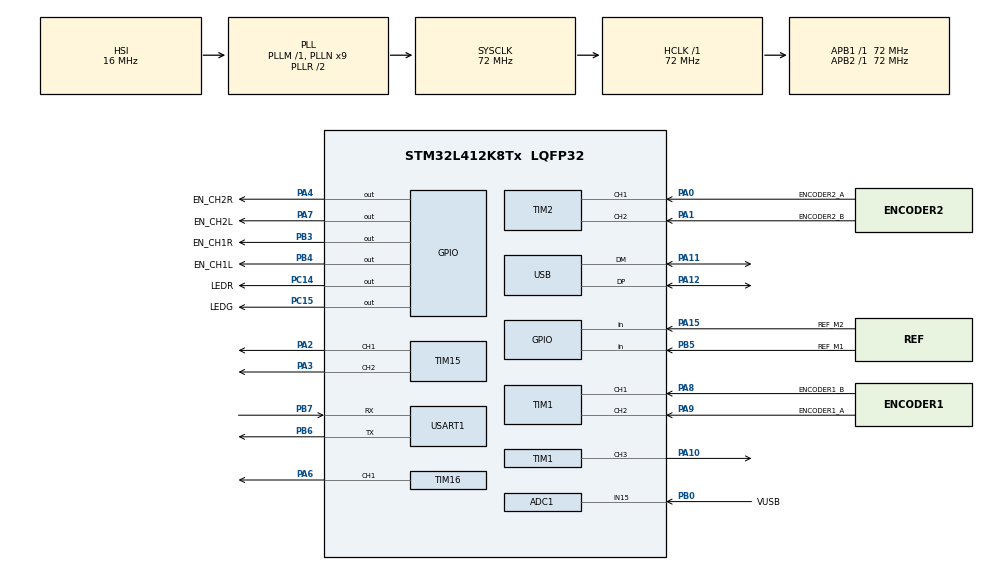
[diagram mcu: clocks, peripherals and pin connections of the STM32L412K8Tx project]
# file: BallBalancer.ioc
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ADC1.Channel-0\#ChannelRegularConversion=ADC_CHANNEL_15
ADC1.NbrOfConversionFlag=1
ADC1.OffsetNumber-0\#ChannelRegularConversion=ADC_OFFSET_NONE
ADC1.Rank-0\#ChannelRegularConversion=1
ADC1.SamplingTime-0\#ChannelRegularConversion=ADC_SAMPLETIME_2CYCLES_5
ADC1.master=1
Mcu.Family=STM32L4
Mcu.Name=STM32L412K8Tx
Mcu.Package=LQFP32
NVIC.PriorityGroup=NVIC_PRIORITYGROUP_4
NVIC.TIM6_IRQn=true\:0\:0\:false\:false\:true\:true\:true\:true
PA0-CK_IN.GPIO_Label=ENCODER2_A
PA0-CK_IN.Signal=S_TIM2_CH1
PA1.GPIO_Label=ENCODER2_B
PA1.Signal=S_TIM2_CH2
PA10.Signal=S_TIM1_CH3
PA11.Mode=Device
PA11.Signal=USB_DM
PA12.Mode=Device
PA12.Signal=USB_DP
PA13\ (JTMS/SWDIO).Mode=Serial_Wire
PA13\ (JTMS/SWDIO).Signal=SYS_JTMS-SWDIO
PA14\ (JTCK/SWCLK).Mode=Serial_Wire
PA14\ (JTCK/SWCLK).Signal=SYS_JTCK-SWCLK
PA15\ (JTDI).GPIO_Label=REF_M2
PA15\ (JTDI).Signal=GPIO_Input
PA2.Signal=S_TIM15_CH1
PA3.Signal=S_TIM15_CH2
PA4.GPIO_Label=EN_CH2R
PA4.Signal=GPIO_Output
PA6.Signal=S_TIM16_CH1
PA7.GPIO_Label=EN_CH2L
PA7.Signal=GPIO_Output
PA8.GPIO_Label=ENCODER1_B
PA8.Signal=S_TIM1_CH1
PA9.GPIO_Label=ENCODER1_A
PA9.Signal=S_TIM1_CH2
PB0.GPIO_Label=VUSB
PB0.Signal=ADCx_IN15
PB3\ (JTDO/TRACESWO).GPIO_Label=EN_CH1R
PB3\ (JTDO/TRACESWO).Signal=GPIO_Output
PB4\ (NJTRST).GPIO_Label=EN_CH1L
PB4\ (NJTRST).Signal=GPIO_Output
PB5.GPIO_Label=REF_M1
PB5.Signal=GPIO_Input
PB6.Mode=Asynchronous
PB6.Signal=USART1_TX
PB7.Mode=Asynchronous
PB7.Signal=USART1_RX
PC14-OSC32_IN\ (PC14).GPIO_Label=LEDR
PC14-OSC32_IN\ (PC14).Signal=GPIO_Output
PC15-OSC32_OUT\ (PC15).GPIO_Label=LEDG
PC15-OSC32_OUT\ (PC15).Signal=GPIO_Output
ProjectManager.HeapSize=0x200
ProjectManager.StackSize=0x400
ProjectManager.TargetToolchain=STM32CubeIDE
RCC.ADCFreq_Value=72000000
RCC.AHBFreq_Value=72000000
RCC.APB1Freq_Value=72000000
RCC.APB1TimFreq_Value=72000000
RCC.APB2Freq_Value=72000000
RCC.APB2TimFreq_Value=72000000
RCC.CK48CLockSelection=RCC_USBCLKSOURCE_HSI48
RCC.CortexFreq_Value=72000000
RCC.HCLKFreq_Value=72000000
RCC.HSE_VALUE=8000000
RCC.HSI48_VALUE=48000000
RCC.HSI_VALUE=16000000
RCC.LSE_VALUE=32768
RCC.MSI_VALUE=4000000
RCC.PLLN=9
RCC.PLLSourceVirtual=RCC_PLLSOURCE_HSI
RCC.SYSCLKFreq_VALUE=72000000
RCC.SYSCLKSource=RCC_SYSCLKSOURCE_PLLCLK
RCC.USBFreq_Value=48000000
RCC.VCOOutputFreq_Value=144000000
SH.ADCx_IN15.0=ADC1_IN15,IN15-Single-Ended
SH.S_TIM15_CH1.0=TIM15_CH1,PWM Generation1 CH1
SH.S_TIM15_CH2.0=TIM15_CH2,PWM Generation2 CH2
SH.S_TIM16_CH1.0=TIM16_CH1,PWM Generation1 CH1
SH.S_TIM1_CH1.0=TIM1_CH1,Encoder_Interface
SH.S_TIM1_CH2.0=TIM1_CH2,Encoder_Interface
SH.S_TIM1_CH3.0=TIM1_CH3,PWM Generation3 CH3
SH.S_TIM2_CH1.0=TIM2_CH1,Encoder_Interface
SH.S_TIM2_CH2.0=TIM2_CH2,Encoder_Interface
TIM1.Channel-PWM\ Generation3\ CH3=TIM_CHANNEL_3
TIM15.Channel-PWM\ Generation1\ CH1=TIM_CHANNEL_1
TIM15.Channel-PWM\ Generation2\ CH2=TIM_CHANNEL_2
TIM16.Channel=TIM_CHANNEL_1
TIM6.Period=35999
TIM6.Prescaler=2
USART1.VirtualMode-Asynchronous=VM_ASYNC
VP_TIM16_VS_ClockSourceINT.Mode=Enable_Timer
VP_TIM6_VS_ClockSourceINT.Mode=Enable_Timer
board=custom

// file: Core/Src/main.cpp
/* USER CODE BEGIN Header */
/**
  ******************************************************************************
  * @file           : main.c
  * @brief          : Main program body
  ******************************************************************************
  * @attention
  *
  * Copyright (c) 2023 STMicroelectronics.
  * All rights reserved.
  *
  * This software is licensed under terms that can be found in the LICENSE file
  * in the root directory of this software component.
  * If no LICENSE file comes with this software, it is provided AS-IS.
  *
  ******************************************************************************
  */
/* USER CODE END Header */
#include "main.h"
#include "adc.h"
#include "tim.h"
#include "usart.h"
#include "usb.h"
#include "gpio.h"

/* USER CODE BEGIN Includes */
#include "AppMain/ApplicationMain.h"
/* USER CODE END Includes */

/* USER CODE BEGIN PV */
  ApplicationMain applicationMain = ApplicationMain();
/* USER CODE END PV */

void SystemClock_Config(void);

int main(void)
{

  /* MCU Configuration--------------------------------------------------------*/

  /* Reset of all peripherals, Initializes the Flash interface and the Systick. */
  HAL_Init();

  /* Configure the system clock */
  SystemClock_Config();

  /* Initialize all configured peripherals */
  MX_GPIO_Init();
  MX_TIM1_Init();
  MX_TIM2_Init();
  MX_TIM15_Init();
  MX_TIM16_Init();
  MX_USART1_UART_Init();
  MX_USB_PCD_Init();
  MX_ADC1_Init();
  MX_TIM6_Init();
  /* USER CODE BEGIN 2 */
  applicationMain.StartUp();
  /* USER CODE END 2 */

  /* Infinite loop */
  while (1)
  {

  }
}

void SystemClock_Config(void)
{
  RCC_OscInitTypeDef RCC_OscInitStruct = {0};
  RCC_ClkInitTypeDef RCC_ClkInitStruct = {0};

  /** Configure the main internal regulator output voltage
  */
  if (HAL_PWREx_ControlVoltageScaling(PWR_REGULATOR_VOLTAGE_SCALE1) != HAL_OK)
  {
    Error_Handler();
  }

  /** Initializes the RCC Oscillators according to the specified parameters
  * in the RCC_OscInitTypeDef structure.
  */
  RCC_OscInitStruct.OscillatorType = RCC_OSCILLATORTYPE_HSI48|RCC_OSCILLATORTYPE_HSI;
  RCC_OscInitStruct.HSIState = RCC_HSI_ON;
  RCC_OscInitStruct.HSI48State = RCC_HSI48_ON;
  RCC_OscInitStruct.HSICalibrationValue = RCC_HSICALIBRATION_DEFAULT;
  RCC_OscInitStruct.PLL.PLLState = RCC_PLL_ON;
  RCC_OscInitStruct.PLL.PLLSource = RCC_PLLSOURCE_HSI;
  RCC_OscInitStruct.PLL.PLLM = 1;
  RCC_OscInitStruct.PLL.PLLN = 9;
  RCC_OscInitStruct.PLL.PLLQ = RCC_PLLQ_DIV2;
  RCC_OscInitStruct.PLL.PLLR = RCC_PLLR_DIV2;
  if (HAL_RCC_OscConfig(&RCC_OscInitStruct) != HAL_OK)
  {
    Error_Handler();
  }

  /** Initializes the CPU, AHB and APB buses clocks
  */
  RCC_ClkInitStruct.ClockType = RCC_CLOCKTYPE_HCLK|RCC_CLOCKTYPE_SYSCLK
                              |RCC_CLOCKTYPE_PCLK1|RCC_CLOCKTYPE_PCLK2;
  RCC_ClkInitStruct.SYSCLKSource = RCC_SYSCLKSOURCE_PLLCLK;
  RCC_ClkInitStruct.AHBCLKDivider = RCC_SYSCLK_DIV1;
  RCC_ClkInitStruct.APB1CLKDivider = RCC_HCLK_DIV1;
  RCC_ClkInitStruct.APB2CLKDivider = RCC_HCLK_DIV1;

  if (HAL_RCC_ClockConfig(&RCC_ClkInitStruct, FLASH_LATENCY_4) != HAL_OK)
  {
    Error_Handler();
  }
}

/* USER CODE BEGIN 4 */

void HAL_TIM_PeriodElapsedCallback(TIM_HandleTypeDef *htim){

	if(htim->Instance == TIM6){
		applicationMain.taskhandler.UpdateTaskhandler();
	}

}

/* USER CODE END 4 */

void Error_Handler(void)
{
  __disable_irq();
  while (1)
  {
  }
}
